VERSION "1.2.0"

NS_ :

BS_:

BU_: CAESAR ENS_CAN0 CAIUS VCU GPS TIM EURECAT_NOBU

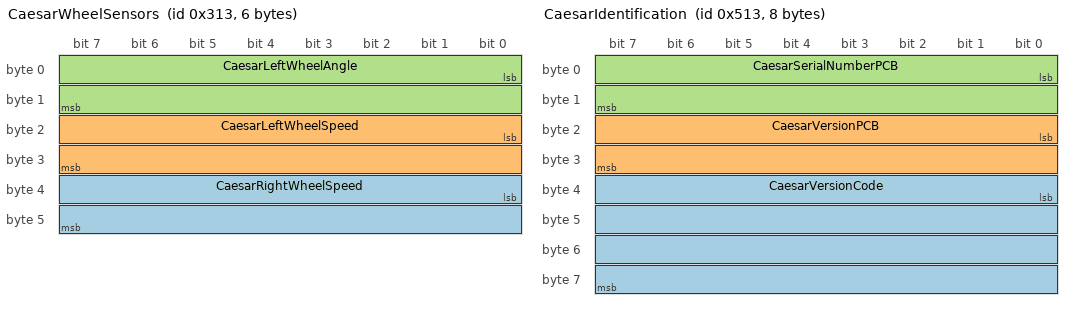
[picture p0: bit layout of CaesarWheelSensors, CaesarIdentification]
BO_ 787 CaesarWheelSensors: 6 CAESAR
 SG_ CaesarRightWheelSpeed : 32|16@1- (1,0) [-32768|32767] "mm/s"  EURECAT_NOBU
 SG_ CaesarLeftWheelSpeed : 16|16@1- (1,0) [-32768|32767] "mm/s"  EURECAT_NOBU
 SG_ CaesarLeftWheelAngle : 0|16@1- (0.1,0) [-3276.8|3276.7] "deg"  EURECAT_NOBU

BO_ 1299 CaesarIdentification: 8 CAESAR
 SG_ CaesarVersionCode : 32|32@1+ (1,0) [0|4294967295] "number"  Default
 SG_ CaesarVersionPCB : 16|16@1+ (1,0) [0|65535] "number"  Default
 SG_ CaesarSerialNumberPCB : 0|16@1+ (1,0) [0|65535] "number"  Default

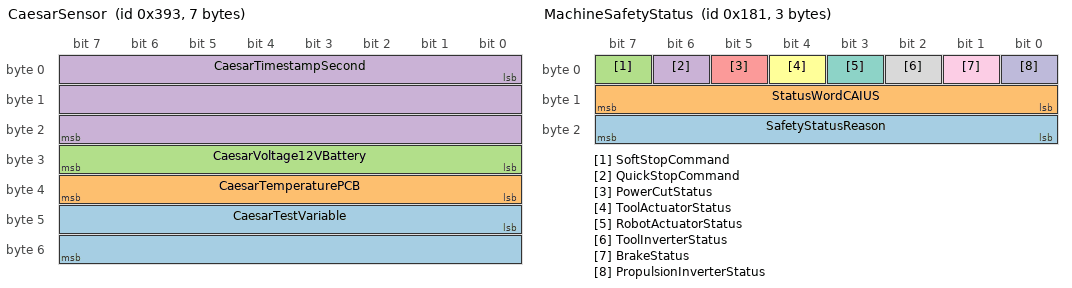
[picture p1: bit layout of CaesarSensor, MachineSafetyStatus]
BO_ 915 CaesarSensor: 7 CAESAR
 SG_ CaesarTestVariable : 40|16@1- (1,0) [-32768|32767] "number"  Default
 SG_ CaesarTemperaturePCB : 32|8@1- (1,0) [-128|127] "Celsius"  Default
 SG_ CaesarVoltage12VBattery : 24|8@1+ (0.1,0) [0|25.5] "volt"  Default
 SG_ CaesarTimestampSecond : 0|24@1+ (1,0) [0|16777215] "second"  Default

BO_ 1043 CaesarLogs: 8 CAESAR
 SG_ CaesarStartNumber : 16|16@1+ (1,0) [0|65535] "number"  Default
 SG_ CaesarHours : 0|16@1+ (0.1,0) [0|6553.5] "hour"  Default

BO_ 886 ENSCommandCaesar: 2 ENS_CAN0
 SG_ ENSPWMCommand : 0|16@1- (1,0) [0|1023] "number"  CAESAR

BO_ 0 CANOpenNmt: 2 CAIUS
 SG_ NodeId : 8|8@1+ (1,0) [0|255] ""  ENS_CAN0
 SG_ CANOpenChangeState : 0|8@1+ (1,0) [0|255] ""  ENS_CAN0

BO_ 1153 CaiusVersion: 2 CAIUS
 SG_ CaiusVersion : 0|16@1+ (1,0) [0|65535] ""  EXT

BO_ 385 MachineSafetyStatus: 3 CAIUS
 SG_ SafetyStatusReason : 16|8@1+ (1,0) [0|255] "enum"  VCU
 SG_ StatusWordCAIUS : 8|8@1+ (1,0) [0|255] "enum"  VCU
 SG_ SoftStopCommand : 7|1@1+ (1,0) [0|1] "boolean"  VCU
 SG_ QuickStopCommand : 6|1@1+ (1,0) [0|1] "boolean"  VCU
 SG_ PowerCutStatus : 5|1@1+ (1,0) [0|1] "boolean"  VCU
 SG_ ToolActuatorStatus : 4|1@1+ (1,0) [0|1] "boolean"  VCU
 SG_ RobotActuatorStatus : 3|1@1+ (1,0) [0|1] "boolean"  VCU
 SG_ ToolInverterStatus : 2|1@1+ (1,0) [0|1] "boolean"  VCU
 SG_ BrakeStatus : 1|1@1+ (1,0) [0|1] "boolean"  VCU
 SG_ PropulsionInverterStatus : 0|1@1+ (1,0) [0|1] "boolean"  VCU

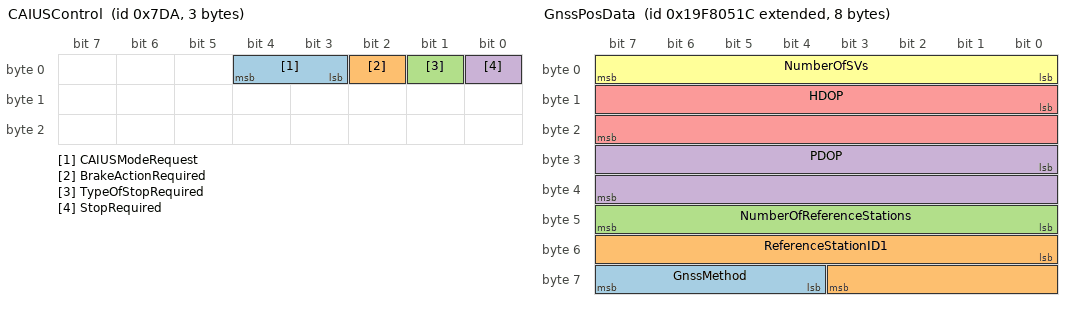
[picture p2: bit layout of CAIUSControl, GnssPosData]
BO_ 2010 CAIUSControl: 3 VCU
 SG_ CAIUSModeRequest : 3|2@1+ (1,0) [0|2] "enum"  CAIUS
 SG_ BrakeActionRequired : 2|1@1+ (1,0) [0|1] "boolean"  CAIUS
 SG_ TypeOfStopRequired : 1|1@1+ (1,0) [0|1] "boolean"  CAIUS
 SG_ StopRequired : 0|1@1+ (1,0) [0|1] "boolean"  CAIUS

BO_ 2314731788 GnssWgs84: 8 GPS
 SG_ Longitude : 32|32@1- (1e-07,0) [-180|180] "deg"  EURECAT_NOBU
 SG_ Latitude : 0|32@1- (1e-07,0) [-90|90] "deg"  EURECAT_NOBU

BO_ 2583168284 GnssPosData: 8 GPS
 SG_ GnssMethod : 60|4@1+ (1,0) [0|15] ""  SPRAYER
 SG_ ReferenceStationID1 : 48|12@1+ (1,0) [0|4095] ""  SPRAYER
 SG_ NumberOfReferenceStations : 40|8@1+ (1,0) [0|252] ""  SPRAYER
 SG_ PDOP : 24|16@1- (0.01,0) [-327.64|327.64] ""  SPRAYER
 SG_ HDOP : 8|16@1- (0.01,0) [-327.64|327.64] ""  SPRAYER
 SG_ NumberOfSVs : 0|8@1+ (1,0) [0|252] ""  SPRAYER

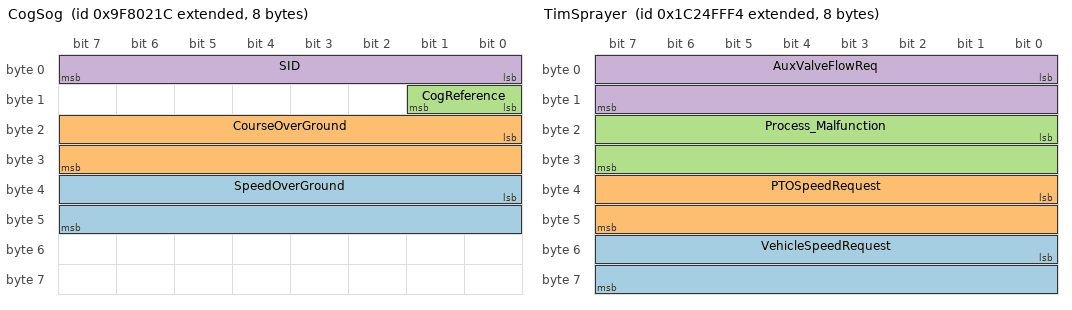
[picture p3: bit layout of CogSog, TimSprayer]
BO_ 2314732060 CogSog: 8 GPS
 SG_ SpeedOverGround : 32|16@1+ (0.01,0) [0|655.32] "m/s"  SPRAYER
 SG_ CourseOverGround : 16|16@1+ (0.0001,0) [0|6.2831] "rad"  SPRAYER
 SG_ CogReference : 8|2@1+ (1,0) [0|3] ""  SPRAYER
 SG_ SID : 0|8@1+ (1,0) [0|252] ""  SPRAYER

BO_ 2619670516 TimSprayer: 8 TIM
 SG_ VehicleSpeedRequest : 48|16@1- (0.001,0) [-32768|32767] "m/s"  EURECAT_NOBU
 SG_ PTOSpeedRequest : 32|16@1+ (1,0) [0|1004] "rpm"  EURECAT_NOBU
 SG_ Process_Malfunction : 16|16@1+ (1,0) [0|3] ""  EURECAT_NOBU
 SG_ AuxValveFlowReq : 0|16@1+ (1,0) [0|3] ""  EURECAT_NOBU

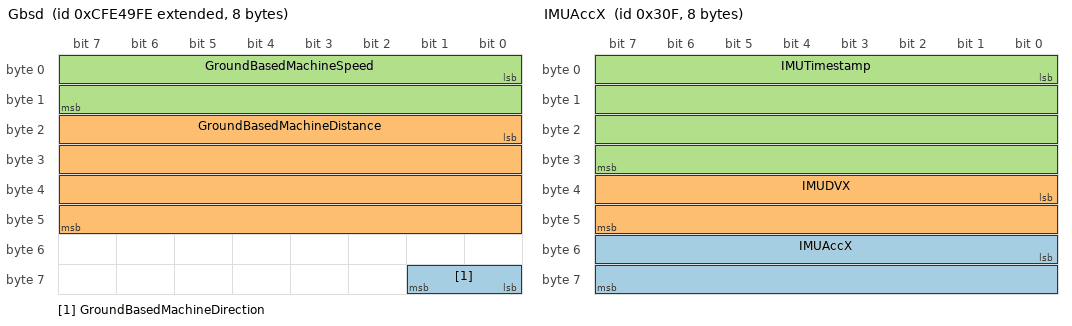
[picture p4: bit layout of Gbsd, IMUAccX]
BO_ 2365475326 Gbsd: 8 EURECAT_NOBU
 SG_ GroundBasedMachineDirection : 56|2@1+ (1,0) [0|3] "" SPRAYER
 SG_ GroundBasedMachineDistance : 16|32@1+ (0.001,0) [0|4211080] "m" SPRAYER
 SG_ GroundBasedMachineSpeed : 0|16@1+ (0.001,0) [0|64.255] "m/s" SPRAYER

BO_ 2314731804 NobuGnssWgs84: 8 EURECAT_NOBU
 SG_ Longitude : 32|32@1- (1e-07,0) [-180|180] "deg"  SPRAYER
 SG_ Latitude : 0|32@1+ (1e-07,0) [-90|90] "deg"  SPRAYER

BO_ 783 IMUAccX: 8 ENS_CAN0
 SG_ IMUAccX : 48|16@1- (0.001,0) [-0.032768|0.032767] "m/s²"  EXT
 SG_ IMUDVX : 32|16@1- (0.001,0) [-0.032768|0.032767] "m/s"  EXT
 SG_ IMUTimestamp : 0|32@1+ (1,0) [0|4294967295] "ms"  EXT

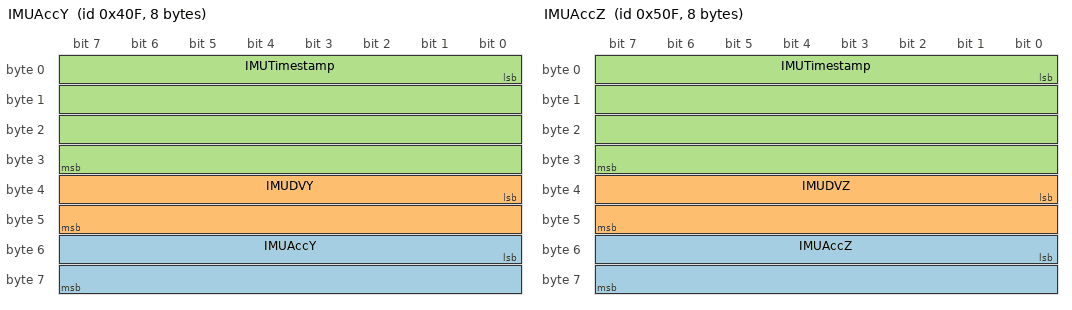
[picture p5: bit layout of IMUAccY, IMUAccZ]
BO_ 1039 IMUAccY: 8 ENS_CAN0
 SG_ IMUAccY : 48|16@1- (0.001,0) [-0.032768|0.032767] "m/s²"  EXT
 SG_ IMUDVY : 32|16@1- (0.001,0) [-0.032768|0.032767] "m/s"  EXT
 SG_ IMUTimestamp : 0|32@1+ (1,0) [0|4294967295] "ms"  EXT

BO_ 1295 IMUAccZ: 8 ENS_CAN0
 SG_ IMUAccZ : 48|16@1- (0.001,0) [-0.032768|0.032767] "m/s²"  EXT
 SG_ IMUDVZ : 32|16@1- (0.001,0) [-0.032768|0.032767] "m/s"  EXT
 SG_ IMUTimestamp : 0|32@1+ (1,0) [0|4294967295] "ms"  EXT

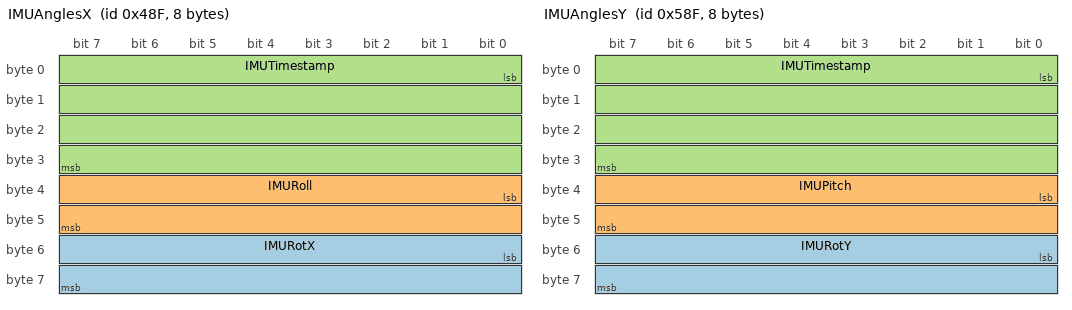
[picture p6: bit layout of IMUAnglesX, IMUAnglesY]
BO_ 1167 IMUAnglesX: 8 ENS_CAN0
 SG_ IMURotX : 48|16@1- (0.0001,0) [-3.2768|3.2767] "rad/s"  EXT
 SG_ IMURoll : 32|16@1- (0.0001,0) [-3.2768|3.2767] "rad"  EXT
 SG_ IMUTimestamp : 0|32@1+ (1,0) [0|4294967295] "ms"  EXT

BO_ 1423 IMUAnglesY: 8 ENS_CAN0
 SG_ IMURotY : 48|16@1- (0.0001,0) [-3.2768|3.2767] "rad/s"  EXT
 SG_ IMUPitch : 32|16@1- (0.0001,0) [-3.2768|3.2767] "rad"  EXT
 SG_ IMUTimestamp : 0|32@1+ (1,0) [0|4294967295] "ms"  EXT

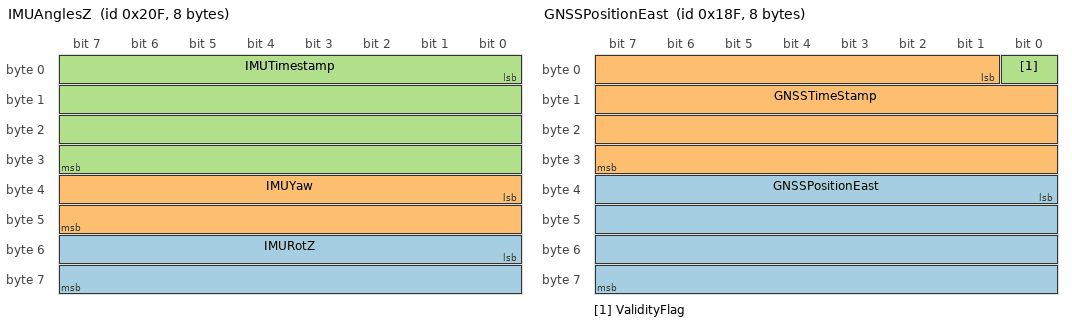
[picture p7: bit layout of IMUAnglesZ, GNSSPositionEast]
BO_ 527 IMUAnglesZ: 8 ENS_CAN0
 SG_ IMURotZ : 48|16@1- (0.0001,0) [-3.2768|3.2767] "rad/s"  EXT
 SG_ IMUYaw : 32|16@1- (0.0001,0) [-3.2768|3.2767] "rad"  EXT
 SG_ IMUTimestamp : 0|32@1+ (1,0) [0|4294967295] "ms"  EXT

BO_ 399 GNSSPositionEast: 8 ENS_CAN0
 SG_ GNSSPositionEast : 32|32@1- (0.001,0) [-100000|100000] "m"  EXT
 SG_ GNSSTimeStamp : 1|31@1+ (1,0) [0|2147483647] "ms"  EXT
 SG_ ValidityFlag : 0|1@1+ (1,0) [0|1] "boolean"  EXT

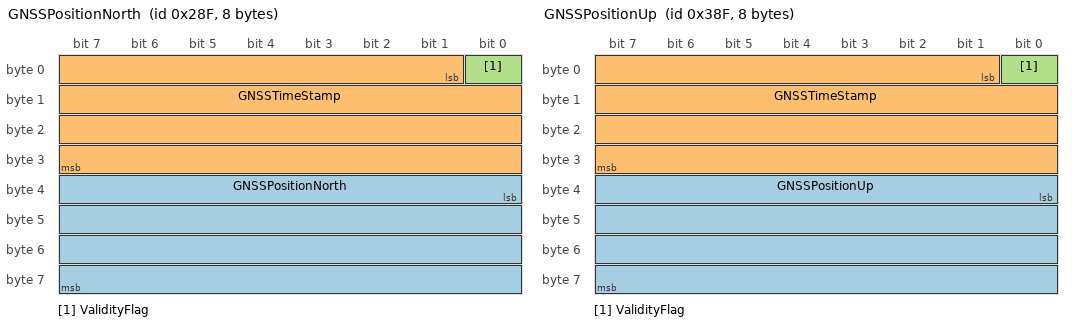
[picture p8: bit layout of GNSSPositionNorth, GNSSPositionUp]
BO_ 655 GNSSPositionNorth: 8 ENS_CAN0
 SG_ GNSSPositionNorth : 32|32@1- (0.001,0) [-100000|100000] "m"  EXT
 SG_ GNSSTimeStamp : 1|31@1+ (1,0) [0|2147483647] "ms"  EXT
 SG_ ValidityFlag : 0|1@1+ (1,0) [0|1] "boolean"  EXT

BO_ 911 GNSSPositionUp: 8 ENS_CAN0
 SG_ GNSSPositionUp : 32|32@1- (0.001,0) [-100000|100000] "m"  EXT
 SG_ GNSSTimeStamp : 1|31@1+ (1,0) [0|2147483647] "ms"  EXT
 SG_ ValidityFlag : 0|1@1+ (1,0) [0|1] "boolean"  EXT

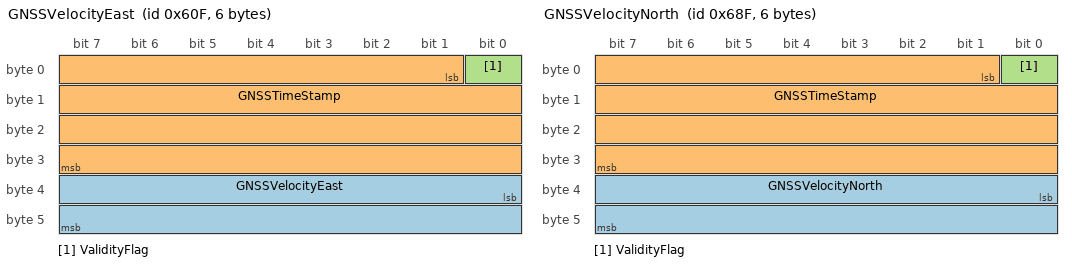
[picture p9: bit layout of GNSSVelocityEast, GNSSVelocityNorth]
BO_ 1551 GNSSVelocityEast: 6 ENS_CAN0
 SG_ GNSSVelocityEast : 32|16@1- (0.001,0) [-32|32] "m/s"  EXT
 SG_ GNSSTimeStamp : 1|31@1+ (1,0) [0|2147483647] "ms"  EXT
 SG_ ValidityFlag : 0|1@1+ (1,0) [0|1] "boolean"  EXT

BO_ 1679 GNSSVelocityNorth: 6 ENS_CAN0
 SG_ GNSSVelocityNorth : 32|16@1- (0.001,0) [-32|32] "m/s"  EXT
 SG_ GNSSTimeStamp : 1|31@1+ (1,0) [0|2147483647] "ms"  EXT
 SG_ ValidityFlag : 0|1@1+ (1,0) [0|1] "boolean"  EXT

BO_ 1809 HeartbeatENS: 1 ENS_CAN0
 SG_ CANOpenStatusENS : 0|8@1+ (1,0) [0|1] "enum"  CAIUS

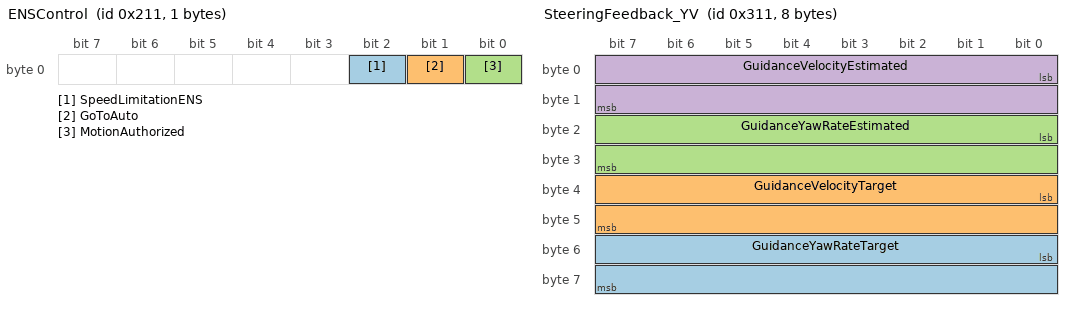
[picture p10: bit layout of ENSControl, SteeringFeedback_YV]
BO_ 529 ENSControl: 1 CAIUS
 SG_ SpeedLimitationENS : 2|1@1+ (1,0) [0|1] "boolean"  ENS_CAN0
 SG_ GoToAuto : 1|1@1+ (1,0) [0|1] "boolean"  ENS_CAN0
 SG_ MotionAuthorized : 0|1@1+ (1,0) [0|1] "boolean"  ENS_CAN0

BO_ 401 ENSStatus: 2 ENS_CAN0
 SG_ MissionWidth : 16|8@1+ (0.1,0) [0|3] "m"  EURECAT_NOBU
 SG_ StatusWordENS : 8|8@1+ (1,0) [0|255] "enum"  CAIUS
 SG_ RequestMotion : 0|1@1+ (1,0) [0|1] "boolean"  CAIUS

BO_ 1298 StatePsiDot: 8 ENS_CAN0
 SG_ PsiDot : 32|32@1- (1e-06,0) [-2147.483648|2147.483647] "rad/s"  EXT
 SG_ StateTickTime : 0|32@1+ (1,0) [0|4294967295] "ms"  EXT

BO_ 1170 StateVelocityLat: 8 ENS_CAN0
 SG_ VelocityLat : 32|32@1- (0.001,0) [-2147483.648|2147483.647] "m/s"  EXT
 SG_ StateTickTime : 0|32@1+ (1,0) [0|4294967295] "ms"  EXT

BO_ 1042 StateVelocityLongi: 8 ENS_CAN0
 SG_ VelocityLongi : 32|32@1- (0.001,0) [-2147483.648|2147483.647] "m/s"  EXT
 SG_ StateTickTime : 0|32@1+ (1,0) [0|4294967295] "ms"  EXT

BO_ 914 StatePsi: 8 ENS_CAN0
 SG_ Psi : 32|32@1- (1e-06,0) [-2147.483648|2147.483647] "rad"  EXT
 SG_ StateTickTime : 0|32@1+ (1,0) [0|4294967295] "ms"  EXT

BO_ 658 StatePositionN: 8 ENS_CAN0
 SG_ PositionN : 32|32@1- (0.001,0) [-2147483.648|2147483.647] "m"  EXT
 SG_ StateTickTime : 0|32@1+ (1,0) [0|4294967295] "ms"  EXT

BO_ 402 StatePositionE: 8 ENS_CAN0
 SG_ PositionE : 32|32@1- (0.001,0) [-2147483.648|2147483.647] "m"  EXT
 SG_ StateTickTime : 0|32@1+ (1,0) [0|4294967295] "ms"  EXT

BO_ 657 SteeringCommands_YV: 4 ENS_CAN0
 SG_ GuidanceYawRateCommand : 16|16@1- (0.0001,0) [-3.2768|3.2767] "rad/s"  VCU
 SG_ GuidanceVelocityCommand : 0|16@1- (0.001,0) [-32.768|32.767] "m/s"  VCU

BO_ 785 SteeringFeedback_YV: 8 VCU
 SG_ GuidanceYawRateTarget : 48|16@1- (0.0001,0) [-3.2768|3.2767] "rad/s"  ENS_CAN0
 SG_ GuidanceVelocityTarget : 32|16@1- (0.001,0) [-32.768|32.767] "m/s"  ENS_CAN0
 SG_ GuidanceYawRateEstimated : 16|16@1- (0.0001,0) [-3.2768|3.2767] "rad/s"  ENS_CAN0
 SG_ GuidanceVelocityEstimated : 0|16@1- (0.001,0) [-32.768|32.767] "m/s"  ENS_CAN0

CM_ BU_ CAIUS "Master on the bus";
CM_ BU_ GPS "GPS Receiver";
CM_ BU_ TIM "TIM Server";
CM_ BU_ EURECAT_NOBU "Eurecat calculator";
CM_ SG_ 0 NodeId "NodeId";
CM_ SG_ 0 CANOpenChangeState "CANOpenChangeState";
CM_ SG_ 1153 CaiusVersion "CAIUS version number";
CM_ SG_ 385 SafetyStatusReason "see dedicated documentation";
CM_ SG_ 385 StatusWordCAIUS "0 Safe 1 Manual-Safe 2 Manual-enable 3 Manual-Armed 4 Auto-Safe 5 Auto-Enable 6 Motion-Imminent 7 Auto-Motion";
CM_ SG_ 385 SoftStopCommand "0: Soft stop required by safety 1: no request";
CM_ SG_ 385 QuickStopCommand "0: emergency stop required by safety 1: no request";
CM_ SG_ 385 PowerCutStatus "1: relay close 0: relay open";
CM_ SG_ 385 ToolActuatorStatus "1: relay close 0: relay open";
CM_ SG_ 385 RobotActuatorStatus "1: relay close 0: relay open";
CM_ SG_ 385 ToolInverterStatus "1: relay close 0: relay open";
CM_ SG_ 385 BrakeStatus "1: brake released 0: brake activated";
CM_ SG_ 385 PropulsionInverterStatus "1: relay close 0: relay open";
CM_ SG_ 2010 CAIUSModeRequest "0 : No_specific_request 1 : Manu_mode_required 2 : Auto_Mode_required";
CM_ SG_ 2010 BrakeActionRequired "0:Brake Activation Required, 1:Brake Release Required";
CM_ SG_ 2010 TypeOfStopRequired "0:Soft Stop Required,1:Quick Stop Required";
CM_ SG_ 2010 StopRequired "0:No Stop required ; 1:Stop Required";
CM_ BO_ 2583168284 "This PGN conveys a comprehensive set of Global Navigation Satellite System (GNSS) parameters, including position information";
CM_ SG_ 2583168284 ReferenceStationID1 "Reference Station ID";
CM_ SG_ 2583168284 NumberOfReferenceStations "Numeric count, event counter, sequence counter";
CM_ SG_ 2583168284 PDOP "Dilution of Precision (DOP) indicates the contribution of satellite configuration geometry to positioning error";
CM_ SG_ 2583168284 HDOP "Dilution of Precision (DOP) indicates the contribution of satellite configuration geometry to positioning error";
CM_ SG_ 2583168284 NumberOfSVs "Numeric count, event counter, sequence counter";
CM_ BO_ 2314732060 "This PGN is a single frame PGN that provides Course Over Ground (COG) and Speed Over Ground (SOG). Being a single frame msg, as opposed to other PGNs that include COG and sOG and are defined as multi-packet, this PGN lends itself to being transmitted more f";
CM_ SG_ 2314732060 CourseOverGround "The direction of the path over ground actually followed by a vessel.";
CM_ SG_ 2314732060 CogReference "0 = True, 1 = Magnetic, 2 = Error, 3 = Null";
CM_ SG_ 2314732060 SID "An upward counting number used to tie related information together between different PGNs. For example, SID would be used to tie together COG, SOG and RAIM values to a given Pos. 255=no valid Pos fix to tie it to. Range 0 to 250 for valid Pos fixes.";
CM_ BO_ 2619670516 "TIM message: TIM client to TIM server";
CM_ SG_ 2619670516 VehicleSpeedRequest "The parameter clarifies the command for the speed control";
CM_ SG_ 2619670516 PTOSpeedRequest "PTO Speed Commands";
CM_ SG_ 2619670516 AuxValveFlowReq "Aux Valve Flow Control";
CM_ BO_ 2365475326 "Ground-based Speed and Distance";
CM_ SG_ 2365475326 GroundBasedMachineDirection "Direction: forward or reverse";
CM_ SG_ 2365475326 GroundBasedMachineDistance "No needed";
CM_ SG_ 2365475326 GroundBasedMachineSpeed "Linear velocity of the platform";
CM_ BO_ 783 "Contains the acceleration vector in x axis";
CM_ SG_ 783 IMUAccX "Free acceleration from which gravity is subtracted on the x axis";
CM_ SG_ 783 IMUDVX "Velocity increment on the x axis";
CM_ SG_ 783 IMUTimestamp "Timestamp from the internal clock of the IMU";
CM_ BO_ 1039 "Contains the acceleration vector in y axis";
CM_ SG_ 1039 IMUAccY "Free acceleration from which gravity is subtracted on the y axis";
CM_ SG_ 1039 IMUDVY "Velocity increment on the y axis";
CM_ SG_ 1039 IMUTimestamp "Timestamp from the internal clock of the IMU";
CM_ BO_ 1295 "Contains the acceleration vector in z axis";
CM_ SG_ 1295 IMUAccZ "Free acceleration from which gravity is subtracted on the z axis";
CM_ SG_ 1295 IMUDVZ "Velocity increment on the z axis";
CM_ SG_ 1295 IMUTimestamp "Timestamp from the internal clock of the IMU";
CM_ BO_ 1167 "Contains the the rate of turn vector and Euler angle in x axis";
CM_ SG_ 1167 IMURotX "Angular velocity about x axis";
CM_ SG_ 1167 IMURoll "Euler angle rotation about x axis (Roll)";
CM_ SG_ 1167 IMUTimestamp "Timestamp from the internal clock of the IMU";
CM_ BO_ 1423 "Contains the the rate of turn vector and Euler angle in y axis";
CM_ SG_ 1423 IMURotY "Angular velocity about y axis";
CM_ SG_ 1423 IMUPitch "Euler angle rotation about y axis (Pitch)";
CM_ SG_ 1423 IMUTimestamp "Timestamp from the internal clock of the IMU";
CM_ BO_ 527 "Contains the the rate of turn vector and Euler angle in z axis";
CM_ SG_ 527 IMURotZ "Angular velocity about z axis";
CM_ SG_ 527 IMUYaw "Euler angle rotation about z axis (Yaw) (unreferenced)";
CM_ SG_ 527 IMUTimestamp "Timestamp from the internal clock of the IMU";
CM_ BO_ 399 "GNSS east position message";
CM_ SG_ 399 GNSSPositionEast "East oriented coordinate of position in local reference system.";
CM_ SG_ 399 GNSSTimeStamp "Timestamp of position data";
CM_ SG_ 399 ValidityFlag "Rtk validity flag of the measure";
CM_ BO_ 655 "GNSS north position message";
CM_ SG_ 655 GNSSPositionNorth "North oriented coordinate of position in local reference system.";
CM_ SG_ 655 GNSSTimeStamp "Timestamp of position data";
CM_ SG_ 655 ValidityFlag "Rtk validity flag of the measure";
CM_ BO_ 911 "GNSS up position message";
CM_ SG_ 911 GNSSPositionUp "Up oriented coordinate of position in local reference system.";
CM_ SG_ 911 GNSSTimeStamp "Timestamp of position data";
CM_ SG_ 911 ValidityFlag "Rtk validity flag of the measure";
CM_ BO_ 1551 "GNSS east velocity message";
CM_ SG_ 1551 GNSSVelocityEast "East oriented coordinate of velocity in local reference system.";
CM_ SG_ 1551 GNSSTimeStamp "Timestamp of position data";
CM_ SG_ 1551 ValidityFlag "Rtk validity flag of the measure";
CM_ BO_ 1679 "GNSS north velocity message";
CM_ SG_ 1679 GNSSVelocityNorth "North oriented coordinate of velocity in local reference system.";
CM_ SG_ 1679 GNSSTimeStamp "Timestamp of position data";
CM_ SG_ 1679 ValidityFlag "Rtk validity flag of the measure";
CM_ BO_ 1809 "Heartbeat with CANOpenStatus";
CM_ SG_ 1809 CANOpenStatusENS "0: Boot-up, 127: Pre-Op, 4: Stopped, 5: Operational";
CM_ BO_ 529 "Aims at controlling ENSStatus according to SafeyStatus";
CM_ SG_ 529 SpeedLimitationENS "Boolean to ask the ENS to respect a speed limit (default 2km/h)";
CM_ SG_ 529 GoToAuto "Boolean to require ENS to switch to autonomous mode (if its own conditions are satisfied";
CM_ SG_ 529 MotionAuthorized "Boolean to authorize ENS to send non-zero steering commands";
CM_ BO_ 401 "Inform CAIUS of ENSStatus and request to change SafetyStatus";
CM_ SG_ 401 MissionWidth "Interrow value";
CM_ SG_ 401 StatusWordENS "0: Manual, 1: Standby, 2: Moving, 3: Frozen, 4: Safe";
CM_ SG_ 401 RequestMotion "Boolean at 1 if ENS is ready to move in autonomus mode";
CM_ BO_ 1298 "Angular velocity state of the vehicle steering";
CM_ SG_ 1298 PsiDot "Angular velocity of the vehicle steering";
CM_ SG_ 1298 StateTickTime "Timestamp from the internal clock of the AGCbox";
CM_ BO_ 1170 "Velocity State in the lateral direction";
CM_ SG_ 1170 VelocityLat "Velocity in the lateral direction";
CM_ SG_ 1170 StateTickTime "Timestamp from the internal clock of the AGCbox";
CM_ BO_ 1042 "Velocity State in the longitudinal direction";
CM_ SG_ 1042 VelocityLongi "Velocity in the longitudinal direction";
CM_ SG_ 1042 StateTickTime "Timestamp from the internal clock of the AGCbox";
CM_ BO_ 914 "Heading state ";
CM_ SG_ 914 Psi "Heading angle (positive definite from North to East)";
CM_ SG_ 914 StateTickTime "Timestamp from the internal clock of the AGCbox";
CM_ BO_ 658 "North position state";
CM_ SG_ 658 PositionN "North oriented coordinate of position in local reference system.";
CM_ SG_ 658 StateTickTime "Timestamp from the internal clock of the AGCbox";
CM_ BO_ 402 "East position state";
CM_ SG_ 402 PositionE "East oriented coordinate of position in local reference system.";
CM_ SG_ 402 StateTickTime "Timestamp from the internal clock of the AGCbox";
CM_ BO_ 657 "Commands to be followed in auto mode";
CM_ SG_ 657 GuidanceYawRateCommand "Other name : PsiDot, definite positive when robot turns right";
CM_ SG_ 657 GuidanceVelocityCommand "Linear velocity";
CM_ BO_ 785 "Needed in both manual and auto mode";
CM_ SG_ 785 GuidanceYawRateTarget "Other name : PsiDot, definite positive when robot turns right";
CM_ SG_ 785 GuidanceVelocityTarget "Linear velocity";
CM_ SG_ 785 GuidanceYawRateEstimated "Other name : PsiDot, definite positive when robot turns right, measured or estimated from measurement, must be independent of GNSS data";
CM_ SG_ 785 GuidanceVelocityEstimated "Linear velocity, measured or estimated from measurement, must be independent of GNSS data";
BA_DEF_ BO_  "GenMsgCycleTime" INT 0 65535;
BA_DEF_DEF_  "GenMsgCycleTime" 0;
BA_ "GenMsgCycleTime" BO_ 787 20;
BA_ "GenMsgCycleTime" BO_ 1299 5000;
BA_ "GenMsgCycleTime" BO_ 915 1000;
BA_ "GenMsgCycleTime" BO_ 1043 5000;
BA_ "GenMsgCycleTime" BO_ 886 20;
BA_ "GenMsgCycleTime" BO_ 1153 1000;
BA_ "GenMsgCycleTime" BO_ 385 20;
BA_ "GenMsgCycleTime" BO_ 2010 20;
BA_ "GenMsgCycleTime" BO_ 2314731788 200;
BA_ "GenMsgCycleTime" BO_ 2583168284 100;
BA_ "GenMsgCycleTime" BO_ 2314732060 250;
BA_ "GenMsgCycleTime" BO_ 2619670516 20;
BA_ "GenMsgCycleTime" BO_ 2365475326 100;
BA_ "GenMsgCycleTime" BO_ 2314731804 200;
BA_ "GenMsgCycleTime" BO_ 783 20;
BA_ "GenMsgCycleTime" BO_ 1039 20;
BA_ "GenMsgCycleTime" BO_ 1295 20;
BA_ "GenMsgCycleTime" BO_ 1167 20;
BA_ "GenMsgCycleTime" BO_ 1423 20;
BA_ "GenMsgCycleTime" BO_ 527 20;
BA_ "GenMsgCycleTime" BO_ 399 200;
BA_ "GenMsgCycleTime" BO_ 655 200;
BA_ "GenMsgCycleTime" BO_ 911 200;
BA_ "GenMsgCycleTime" BO_ 1551 200;
BA_ "GenMsgCycleTime" BO_ 1679 200;
BA_ "GenMsgCycleTime" BO_ 1809 500;
BA_ "GenMsgCycleTime" BO_ 529 50;
BA_ "GenMsgCycleTime" BO_ 401 50;
BA_ "GenMsgCycleTime" BO_ 1298 20;
BA_ "GenMsgCycleTime" BO_ 1170 20;
BA_ "GenMsgCycleTime" BO_ 1042 20;
BA_ "GenMsgCycleTime" BO_ 914 20;
BA_ "GenMsgCycleTime" BO_ 658 20;
BA_ "GenMsgCycleTime" BO_ 402 20;
BA_ "GenMsgCycleTime" BO_ 657 20;
BA_ "GenMsgCycleTime" BO_ 785 20;
VAL_ 2583168284 GnssMethod 14 "Error" 8 "Simulate mode" 7 "Manual input" 6 "Estimated DR mode" 5 "RTK float" 4 "RTK fixed integer" 3 "Precise GNSS" 2 "DGNSS fix" 1 "GNSS fix" 0 "No GPS" ;
VAL_ 2314732060 CogReference 0 "True" 1 "Magnetic" 2 "Error" 3 "Null" ;
VAL_ 2314732060 SID 255 "nVldPsFxTTItTRng0T250FrVldPstnFx" ;
VAL_ 2619670516 PTOSpeedRequest 64511 "ReadyToControl" 64509 "RequestOperatorAction" 64256 "OnSpeedClockwiseSetByTimServer" 32128 "off" 0 "OnSpeedCountSetByTim" ;
VAL_ 2619670516 Process_Malfunction 3 "Ready" 2 "Default" 1 "StopRequest" 0 "ContinueNonStop" ;
VAL_ 2619670516 AuxValveFlowReq 3 "ReadyToControl" 2 "Float" 1 "Block" 0 "ValveFullyOpened" ;
VAL_ 2365475326 GroundBasedMachineDirection 3 "NotAvailable" 2 "ErrorIndication" 1 "Forward" 0 "Reverse" ;
